# MKV31F25612 register map
Vendor: Freescale Semiconductor, Inc.; Series: Kinetis_V; File version: 1.6
CPU: CM4 r0p1, little endian, no MPU, FPU, VTOR, 4 interrupt priority bits
Registers are 32-bit, read-write, reset 0x0 unless marked. A register's access mark holds for its fields unless they carry their own. Offsets are from the block's base; [hi:lo] are bit positions.

## SMC — System Mode Controller
Base 0x4007E000; register names take the prefix SMC_
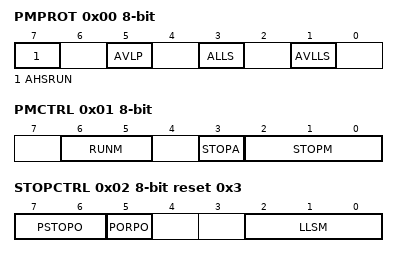
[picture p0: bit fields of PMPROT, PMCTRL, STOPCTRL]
0x00 PMPROT 8-bit — Power Mode Protection register
  [7] AHSRUN — Allow High Speed Run mode
    0=HSRUN is not allowed; 1=HSRUN is allowed
  [5] AVLP — Allow Very-Low-Power Modes
    0=VLPR, VLPW, and VLPS are not allowed; 1=VLPR, VLPW, and VLPS are allowed
  [3] ALLS — Allow Low-Leakage Stop Mode
    0=Any LLSx mode is not allowed; 1=Any LLSx mode is allowed
  [1] AVLLS — Allow Very-Low-Leakage Stop Mode
    0=Any VLLSx mode is not allowed; 1=Any VLLSx mode is allowed
0x01 PMCTRL 8-bit — Power Mode Control register
  [6:5] RUNM — Run Mode Control
    0=Normal Run mode (RUN); 2=Very-Low-Power Run mode (VLPR); 3=High Speed Run mode (HSRUN)
  [3] STOPA ro — Stop Aborted
    0=The previous stop mode entry was successsful; 1=The previous stop mode entry was aborted
  [2:0] STOPM — Stop Mode Control
    0=Normal Stop (STOP); 2=Very-Low-Power Stop (VLPS); 3=Low-Leakage Stop (LLSx); 4=Very-Low-Leakage Stop (VLLSx); 6=Reseved
0x02 STOPCTRL 8-bit reset 0x3 — Stop Control Register
  [7:6] PSTOPO — Partial Stop Option
    0=STOP - Normal Stop mode; 1=PSTOP1 - Partial Stop with both system and bus clocks disabled; 2=PSTOP2 - Partial Stop with system clock disabled and bus clock enabled
  [5] PORPO — POR Power Option
    0=POR detect circuit is enabled in VLLS0; 1=POR detect circuit is disabled in VLLS0
  [2:0] LLSM — LLS or VLLS Mode Control
    0=VLLS0if PMCTRL[STOPM]=VLLSx, Reserved if PMCTRL[STOPM]=LLSx; 1=VLLS1if PMCTRL[STOPM]=VLLSx, Reserved if PMCTRL[STOPM]=LLSx; 2=VLLS2if PMCTRL[STOPM]=VLLSx, LLS2 if PMCTRL[STOPM]=LLSx; 3=VLLS3if PMCTRL[STOPM]=VLLSx, LLS3 if PMCTRL[STOPM]=LLSx
0x03 PMSTAT 8-bit ro reset 0x1 — Power Mode Status register

## PTA — General Purpose Input/Output
Base 0x400FF000; register names take the prefix GPIOA_
0x00 PDOR — Port Data Output Register
  [31:0] PDO — Port Data Output
    0=Logic level 0 is driven on pin, provided pin is configured for general-purpose output; 1=Logic level 1 is driven on pin, provided pin is configured for general-purpose output
0x04 PSOR wo — Port Set Output Register
  [31:0] PTSO — Port Set Output
    0=Corresponding bit in PDORn does not change; 1=Corresponding bit in PDORn is set to logic 1
0x08 PCOR wo — Port Clear Output Register
  [31:0] PTCO — Port Clear Output
    0=Corresponding bit in PDORn does not change; 1=Corresponding bit in PDORn is cleared to logic 0
0x0C PTOR wo — Port Toggle Output Register
  [31:0] PTTO — Port Toggle Output
    0=Corresponding bit in PDORn does not change; 1=Corresponding bit in PDORn is set to the inverse of its existing logic state
0x10 PDIR ro — Port Data Input Register
  [31:0] PDI — Port Data Input
    0=Pin logic level is logic 0, or is not configured for use by digital function; 1=Pin logic level is logic 1
0x14 PDDR — Port Data Direction Register
  [31:0] PDD — Port Data Direction
    0=Pin is configured as general-purpose input, for the GPIO function; 1=Pin is configured as general-purpose output, for the GPIO function

## PTB — General Purpose Input/Output
Base 0x400FF040; register names take the prefix GPIOB_
Registers as PTA.

## PTC — General Purpose Input/Output
Base 0x400FF080; register names take the prefix GPIOC_
Registers as PTA; these are added or differ:
0x08 PCOR wo — Port Clear Output Register
  [31:0] PTCO — Port Clear Output
    0=Corresponding bit in PDORn does not change; 1=Corresponding bit in PDORn is cleared to logic 0

## PTD — General Purpose Input/Output
Base 0x400FF0C0; register names take the prefix GPIOD_
Registers as PTA.

## PTE — General Purpose Input/Output
Base 0x400FF100; register names take the prefix GPIOE_
Registers as PTA.

## MCM — Core Platform Miscellaneous Control Module
Base 0xE0080000; register names take the prefix MCM_
0x08 PLASC 16-bit ro reset 0x1F — Crossbar Switch (AXBS) Slave Configuration
  [7:0] ASC — Each bit in the ASC field indicates whether there is a corresponding connection to the crossbar switch's slave input port.
    0=A bus slave connection to AXBS input port n is absent; 1=A bus slave connection to AXBS input port n is present
0x0A PLAMC 16-bit ro reset 0x17 — Crossbar Switch (AXBS) Master Configuration
  [7:0] AMC — Each bit in the AMC field indicates whether there is a corresponding connection to the AXBS master input port.
    0=A bus master connection to AXBS input port n is absent; 1=A bus master connection to AXBS input port n is present
0x0C PLACR — Crossbar Switch (AXBS) Control Register
  [9] ARB — Arbitration select
    0=Fixed-priority arbitration for the crossbar masters; 1=Round-robin arbitration for the crossbar masters
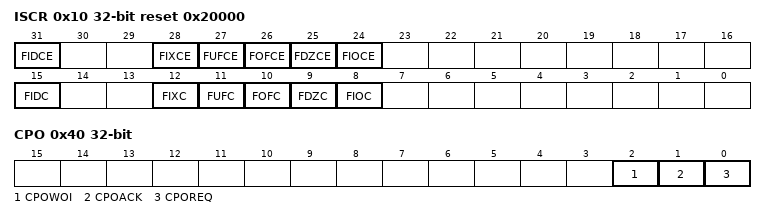
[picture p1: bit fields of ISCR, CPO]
0x10 ISCR reset 0x20000 — Interrupt Status and Control Register
  [31] FIDCE — FPU input denormal interrupt enable
    0=Disable interrupt; 1=Enable interrupt
  [28] FIXCE — FPU inexact interrupt enable
    0=Disable interrupt; 1=Enable interrupt
  [27] FUFCE — FPU underflow interrupt enable
    0=Disable interrupt; 1=Enable interrupt
  [26] FOFCE — FPU overflow interrupt enable
    0=Disable interrupt; 1=Enable interrupt
  [25] FDZCE — FPU divide-by-zero interrupt enable
    0=Disable interrupt; 1=Enable interrupt
  [24] FIOCE — FPU invalid operation interrupt enable
    0=Disable interrupt; 1=Enable interrupt
  [15] FIDC ro — FPU input denormal interrupt status
    0=No interrupt; 1=Interrupt occurred
  [12] FIXC ro — FPU inexact interrupt status
    0=No interrupt; 1=Interrupt occurred
  [11] FUFC ro — FPU underflow interrupt status
    0=No interrupt; 1=Interrupt occurred
  [10] FOFC ro — FPU overflow interrupt status
    0=No interrupt; 1=Interrupt occurred
  [9] FDZC ro — FPU divide-by-zero interrupt status
    0=No interrupt; 1=Interrupt occurred
  [8] FIOC ro — FPU invalid operation interrupt status
    0=No interrupt; 1=Interrupt occurred
0x40 CPO — Compute Operation Control Register
  [2] CPOWOI — Compute Operation wakeup on interrupt
    0=No effect; 1=When set, the CPOREQ is cleared on any interrupt or exception vector fetch
  [1] CPOACK ro — Compute Operation acknowledge
    0=Compute operation entry has not completed or compute operation exit has completed; 1=Compute operation entry has completed or compute operation exit has not completed
  [0] CPOREQ — Compute Operation request
    0=Request is cleared; 1=Request Compute Operation
